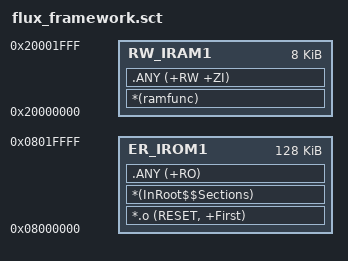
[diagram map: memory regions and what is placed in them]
; flux_framework scatter file
; Same layout as the one Keil generates from the Target memory settings, plus one line:
; section 'ramfunc' (RAMFUNC, see FW/Inc/compiler.h) executes from RAM;
; __main copies it from Flash at startup. SC32R602: Flash 128 KB, RAM 8 KB.

LR_IROM1 0x08000000 0x00020000  {
  ER_IROM1 0x08000000 0x00020000  {
   *.o (RESET, +First)
   *(InRoot$$Sections)
   .ANY (+RO)
  }
  RW_IRAM1 0x20000000 0x00002000  {
   *(ramfunc)
   .ANY (+RW +ZI)
  }
}
